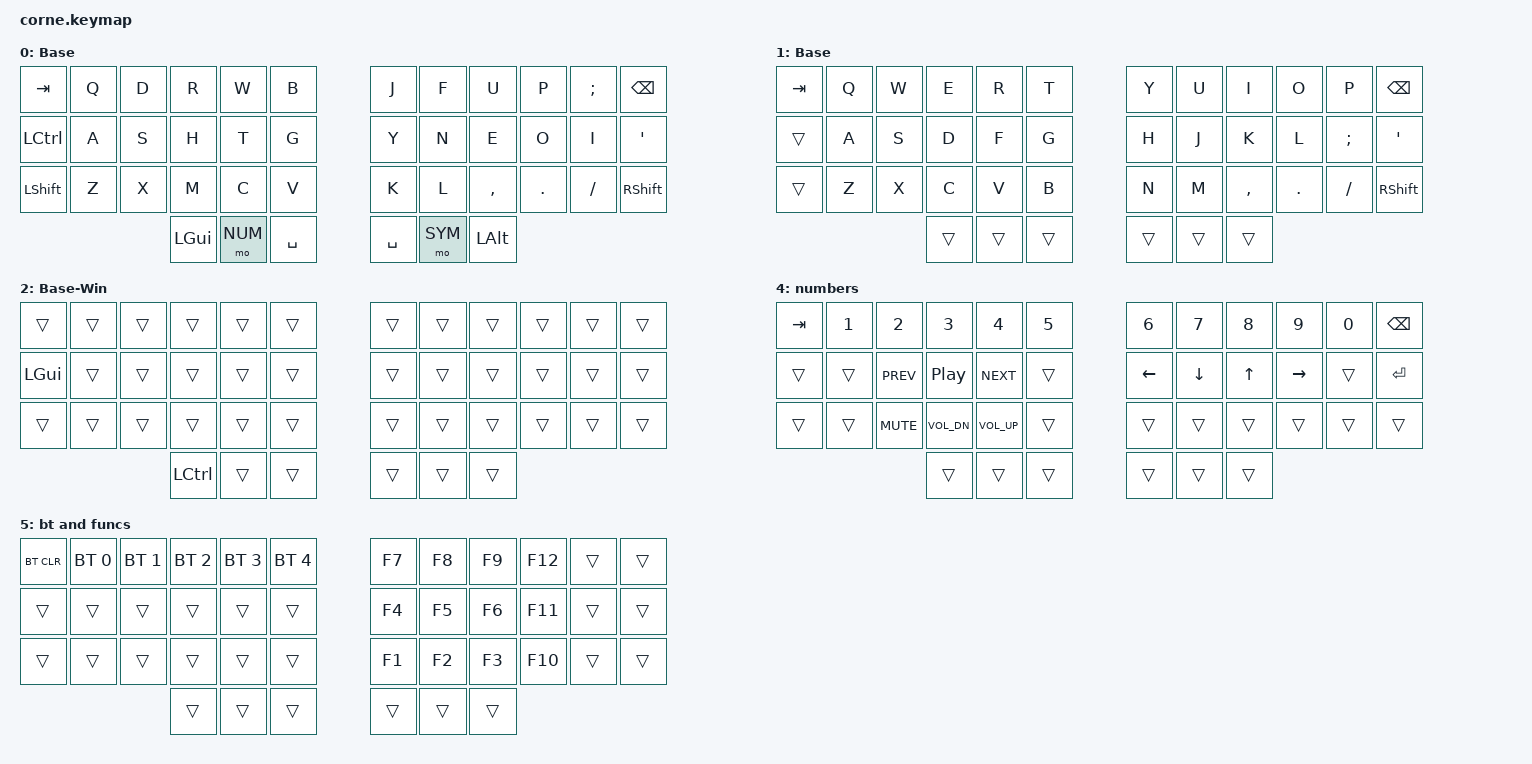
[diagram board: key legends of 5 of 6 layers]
/*
 * Copyright (c) 2020 The ZMK Contributors
 *
 * SPDX-License-Identifier: MIT
 */


// Changes were inspired by:
// https://github.com/infused-kim/zmk-config/blob/chocofi/main/config/chocofi.keymap


// Define layer numbers
#define BASE_WRKMN 0
#define BASE_QWERTY 1
#define WIN_CTRLS 2
#define SYM 3
#define NUM 4
#define FUNC 5


// zmk includes
#include <behaviors.dtsi>
#include <dt-bindings/zmk/keys.h>
#include <dt-bindings/zmk/bt.h>


// personal includes
#include "includes/conditional_layers.dtsi"
#include "includes/combos.dtsi"

&nice_view_spi {
  cs-gpios = <&pro_micro 0 GPIO_ACTIVE_HIGH>;
};

/ {

  keymap {
    compatible = "zmk,keymap";

    Workman {
      label = "Base";
      bindings = <
// ╭────────────────────────┬────────────────────────┬────────────────────────┬────────────────────────┬────────────────────────┬────────────────────────╮    ╭────────────────────────┬────────────────────────┬────────────────────────┬───────────────────────┬───────────────────────┬────────────────────────╮
    &kp TAB                   &kp Q                    &kp D                    &kp R                    &kp W                         &kp B                    &kp J                    &kp F                    &kp U                    &kp P                   &kp SEMI                 &kp BSPC
// ├────────────────────────┼────────────────────────┼────────────────────────┼────────────────────────┼────────────────────────┼────────────────────────┤    ├────────────────────────┼────────────────────────┼────────────────────────┼───────────────────────┼───────────────────────┼────────────────────────┤
//  &kp LGUI                &kp A                    &kp S                    &kp H                    &kp T                         &kp G                    &kp Y                    &kp N                    &kp E                    &kp O                   &kp I                    &kp SQT
    &kp LCTRL                &kp A                    &kp S                    &kp H                    &kp T                         &kp G                    &kp Y                    &kp N                    &kp E                    &kp O                   &kp I                    &kp SQT

// ├────────────────────────┼────────────────────────┼────────────────────────┼────────────────────────┼────────────────────────┼────────────────────────┤    ├────────────────────────┼────────────────────────┼────────────────────────┼───────────────────────┼───────────────────────┼────────────────────────┤
//  &kp LSHFT                 &kp Z                    &kp X                    &kp M                    &kp C                         &kp V                    &kp K                    &kp L                    &kp COMMA                &kp DOT                 &kp FSLH                 &kp RSHFT
    &kp LSHFT                 &kp Z                    &kp X                    &kp M                    &kp C                         &kp V                    &kp K                    &kp L                    &kp COMMA                &kp DOT                 &kp FSLH                 &kp RSHFT

// ╰────────────────────────┴────────────────────────┴────────────────────────┴────────────────────────┼────────────────────────┼────────────────────────┤    ├────────────────────────┼────────────────────────┼────────────────────────┼───────────────────────┼───────────────────────┼────────────────────────╯
//                                                                              &kp LCTRL                 &mo NUM                &kp SPACE                         &kp SPACE                &mo SYM               &kp LALT
                                                                                &kp LGUI                 &mo NUM                &kp SPACE                         &kp SPACE                &mo SYM               &kp LALT
                                //                                            ╰────────────────────────┴────────────────────────┴────────────────────────╯    ╰────────────────────────┴────────────────────────┴────────────────────────╯
                >;
        };

        Qwerty {
      label = "Base";
      bindings = <
// ╭────────────────────────┬────────────────────────┬────────────────────────┬────────────────────────┬────────────────────────┬────────────────────────╮    ╭────────────────────────┬────────────────────────┬────────────────────────┬───────────────────────┬───────────────────────┬────────────────────────╮
    &kp TAB                   &kp Q                    &kp W                    &kp E                    &kp R                         &kp T                    &kp Y                    &kp U                    &kp I                    &kp O                   &kp P                   &kp BSPC
// ├────────────────────────┼────────────────────────┼────────────────────────┼────────────────────────┼────────────────────────┼────────────────────────┤    ├────────────────────────┼────────────────────────┼────────────────────────┼───────────────────────┼───────────────────────┼────────────────────────┤
    &trans                    &kp A                         &kp S                    &kp D                    &kp F                         &kp G                    &kp H                    &kp J                    &kp K                    &kp L                   &kp SEMI                 &kp SQT
// ├────────────────────────┼────────────────────────┼────────────────────────┼────────────────────────┼────────────────────────┼────────────────────────┤    ├────────────────────────┼────────────────────────┼────────────────────────┼───────────────────────┼───────────────────────┼────────────────────────┤
    &trans                     &kp Z                       &kp X                    &kp C                    &kp V                         &kp B                    &kp N                    &kp M                    &kp COMMA                &kp DOT                 &kp FSLH                 &kp RSHFT
// ╰────────────────────────┴────────────────────────┴────────────────────────┴────────────────────────┼────────────────────────┼────────────────────────┤    ├────────────────────────┼────────────────────────┼────────────────────────┼───────────────────────┼───────────────────────┼────────────────────────╯
                                                                                &trans                    &trans                   &trans                         &trans                &trans                           &trans
                                //                                            ╰────────────────────────┴────────────────────────┴────────────────────────╯    ╰────────────────────────┴────────────────────────┴────────────────────────╯
                >;
        };

        Windows {
      label = "Base-Win";
      bindings = <
// ╭────────────────────────┬────────────────────────┬────────────────────────┬────────────────────────┬────────────────────────┬────────────────────────╮    ╭────────────────────────┬────────────────────────┬────────────────────────┬───────────────────────┬───────────────────────┬────────────────────────╮
        &trans                  &trans                  &trans                  &trans                      &trans                  &trans                      &trans                     &trans                   &trans                      &trans              &trans                  &trans
// ├────────────────────────┼────────────────────────┼────────────────────────┼────────────────────────┼────────────────────────┼────────────────────────┤    ├────────────────────────┼────────────────────────┼────────────────────────┼───────────────────────┼───────────────────────┼────────────────────────┤
        &kp LGUI                &trans                  &trans                  &trans                      &trans                  &trans                      &trans                     &trans                   &trans                      &trans              &trans                  &trans
// ├────────────────────────┼────────────────────────┼────────────────────────┼────────────────────────┼────────────────────────┼────────────────────────┤    ├────────────────────────┼────────────────────────┼────────────────────────┼───────────────────────┼───────────────────────┼────────────────────────┤
        &trans                  &trans                  &trans                  &trans                      &trans                  &trans                      &trans                     &trans                   &trans                      &trans              &trans                  &trans
// ╰────────────────────────┴────────────────────────┴────────────────────────┴────────────────────────┼────────────────────────┼────────────────────────┤    ├────────────────────────┼────────────────────────┼────────────────────────┼───────────────────────┼───────────────────────┼────────────────────────╯
                                                                                &kp LCTRL                    &trans                   &trans                         &trans                &trans                           &trans
                                //                                            ╰────────────────────────┴────────────────────────┴────────────────────────╯    ╰────────────────────────┴────────────────────────┴────────────────────────╯
                >;
        };

        raise_layer {
      label = "Raise..?";
      bindings = <
// ╭────────────────────────┬────────────────────────┬────────────────────────┬────────────────────────┬────────────────────────┬────────────────────────╮    ╭────────────────────────┬────────────────────────┬────────────────────────┬───────────────────────┬───────────────────────┬────────────────────────╮
    &kp ESC                   &kp EXCL                 &kp AT                    &kp HASH                &kp DLLR                      &kp PRCNT                &kp CARET                &kp AMPS                 &kp KP_ASTERISK          &kp LPAR                &kp RPAR                 &kp BSPC
// ├────────────────────────┼────────────────────────┼────────────────────────┼────────────────────────┼────────────────────────┼────────────────────────┤    ├────────────────────────┼────────────────────────┼────────────────────────┼───────────────────────┼───────────────────────┼────────────────────────┤
    &trans                    &trans                    &trans                     &trans                    &trans                         &trans                &kp MINUS                &kp EQUAL              &kp LBKT                 &kp RBKT                &kp BSLH                 &kp GRAVE
// ├────────────────────────┼────────────────────────┼────────────────────────┼────────────────────────┼────────────────────────┼────────────────────────┤    ├────────────────────────┼────────────────────────┼────────────────────────┼───────────────────────┼───────────────────────┼────────────────────────┤
    &trans                    &trans                    &trans                    &trans                      &trans                  &kp UNDER                    &kp PLUS                    &kp LBRC                &kp RBRC                 &kp PIPE                 &kp TILDE
// ╰────────────────────────┴────────────────────────┴────────────────────────┴────────────────────────┼────────────────────────┼────────────────────────┤    ├────────────────────────┼────────────────────────┼────────────────────────┼───────────────────────┼───────────────────────┼────────────────────────╯
                                                                                &trans                   &trans                  &trans                         &trans                    &trans                &trans
//                                                                             ╰────────────────────────┴────────────────────────┴────────────────────────╯    ╰────────────────────────┴────────────────────────┴────────────────────────╯
                >;
        };
        lower_layer {
      label = "numbers";
      bindings = <
// ╭────────────────────────┬────────────────────────┬────────────────────────┬────────────────────────┬────────────────────────┬────────────────────────╮    ╭────────────────────────┬────────────────────────┬────────────────────────┬───────────────────────┬───────────────────────┬────────────────────────╮
    &kp TAB                   &kp N1                 &kp N2                    &kp N3                   &kp N4                      &kp N5                        &kp N6                &kp N7                            &kp N8                   &kp N9                &kp N0                 &kp BSPC
// ├────────────────────────┼────────────────────────┼────────────────────────┼────────────────────────┼────────────────────────┼────────────────────────┤    ├────────────────────────┼────────────────────────┼────────────────────────┼───────────────────────┼───────────────────────┼────────────────────────┤
        &trans                    &trans                    &kp C_PREV            &kp C_PP                &kp C_NEXT               &trans                        &kp LEFT                &kp DOWN                        &kp UP                  &kp RIGHT         &trans                   &kp RET
// ├────────────────────────┼────────────────────────┼────────────────────────┼────────────────────────┼────────────────────────┼────────────────────────┤    ├────────────────────────┼────────────────────────┼────────────────────────┼───────────────────────┼───────────────────────┼────────────────────────┤
        &trans                  &trans                  &kp C_MUTE                  &kp C_VOL_DN         &kp C_VOL_UP                    &trans                     &trans                   &trans                      &trans              &trans                  &trans                 &trans
//        &trans                    &trans                    &kp C_MUTE            &kp C_VOL_DOWN          &kp C_VOL_UP                  &trans                    &trans                  &trans                      &trans                  &trans                &trans                  &trans
// ╰────────────────────────┴────────────────────────┴────────────────────────┴────────────────────────┼────────────────────────┼────────────────────────┤    ├────────────────────────┼────────────────────────┼────────────────────────┼───────────────────────┼───────────────────────┼────────────────────────╯
                                                                                &trans                 &trans                  &trans                         &trans                    &trans                &trans
//                                                                             ╰────────────────────────┴────────────────────────┴────────────────────────╯    ╰────────────────────────┴────────────────────────┴────────────────────────╯
                >;
        };

        bluetooth_and_functions {
      label = "bt and funcs";
      bindings = <
// ╭────────────────────────┬────────────────────────┬────────────────────────┬────────────────────────┬────────────────────────┬────────────────────────╮    ╭────────────────────────┬────────────────────────┬────────────────────────┬───────────────────────┬───────────────────────┬────────────────────────╮
    &bt BT_CLR                  &bt BT_SEL 0             &bt BT_SEL 1            &bt BT_SEL 2            &bt BT_SEL 3            &bt BT_SEL 4                   &kp F7                &kp F8                 &kp F9                      &kp F12                &trans                 &trans
// ├────────────────────────┼────────────────────────┼────────────────────────┼────────────────────────┼────────────────────────┼────────────────────────┤    ├────────────────────────┼────────────────────────┼────────────────────────┼───────────────────────┼───────────────────────┼────────────────────────┤
    &trans                      &trans                    &trans                    &trans               &trans                &trans                           &kp F4                     &kp F5                    &kp F6                 &kp F11                &trans                 &trans
// ├────────────────────────┼────────────────────────┼────────────────────────┼────────────────────────┼────────────────────────┼────────────────────────┤    ├────────────────────────┼────────────────────────┼────────────────────────┼───────────────────────┼───────────────────────┼────────────────────────┤
    &trans                      &trans                    &trans                    &trans                    &trans                      &trans                  &kp F1                    &kp F2                    &kp F3                    &kp F10                      &trans                &trans
// ╰────────────────────────┴────────────────────────┴────────────────────────┴────────────────────────┼────────────────────────┼────────────────────────┤    ├────────────────────────┼────────────────────────┼────────────────────────┼───────────────────────┼───────────────────────┼────────────────────────╯
                                                                                &trans                   &trans                  &trans                         &trans                    &trans                 &trans
//                                                                            ╰────────────────────────┴────────────────────────┴────────────────────────╯    ╰────────────────────────┴────────────────────────┴────────────────────────╯
                >;
        };
  };
};
